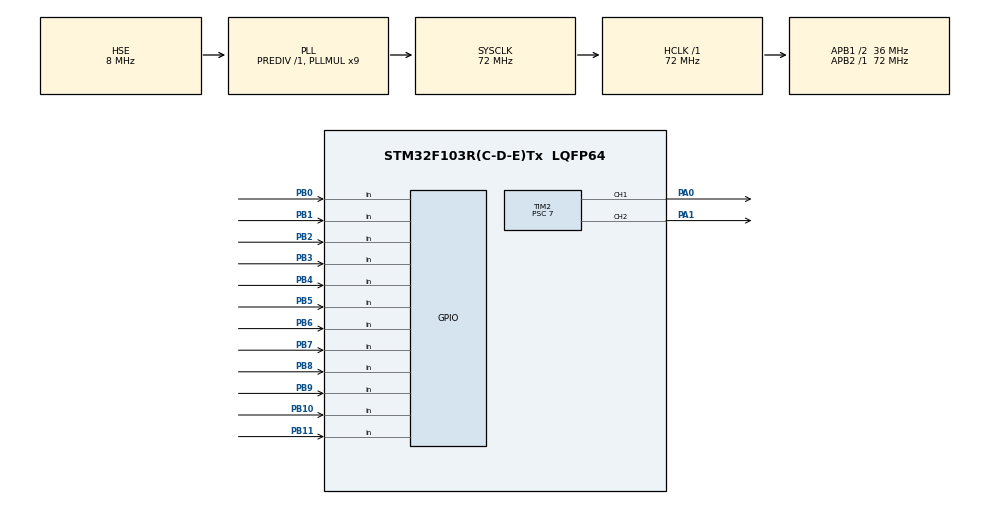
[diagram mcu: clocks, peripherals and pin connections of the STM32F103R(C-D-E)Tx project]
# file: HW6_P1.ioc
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Mcu.Family=STM32F1
Mcu.Name=STM32F103R(C-D-E)Tx
Mcu.Package=LQFP64
NVIC.PriorityGroup=NVIC_PRIORITYGROUP_4
PA0-WKUP.Signal=S_TIM2_CH1_ETR
PA1.Signal=S_TIM2_CH2
PA13.Mode=Serial_Wire
PA13.Signal=SYS_JTMS-SWDIO
PA14.Mode=Serial_Wire
PA14.Signal=SYS_JTCK-SWCLK
PB0.GPIO_PuPd=GPIO_PULLDOWN
PB0.Signal=GPIO_Input
PB1.GPIO_PuPd=GPIO_PULLDOWN
PB1.Signal=GPIO_Input
PB10.GPIO_PuPd=GPIO_PULLDOWN
PB10.Signal=GPIO_Input
PB11.GPIO_PuPd=GPIO_PULLDOWN
PB11.Signal=GPIO_Input
PB2.GPIO_PuPd=GPIO_PULLDOWN
PB2.Signal=GPIO_Input
PB3.GPIO_PuPd=GPIO_PULLDOWN
PB3.Signal=GPIO_Input
PB4.GPIO_PuPd=GPIO_PULLDOWN
PB4.Signal=GPIO_Input
PB5.GPIO_PuPd=GPIO_PULLDOWN
PB5.Signal=GPIO_Input
PB6.GPIO_PuPd=GPIO_PULLDOWN
PB6.Signal=GPIO_Input
PB7.GPIO_PuPd=GPIO_PULLDOWN
PB7.Signal=GPIO_Input
PB8.GPIO_PuPd=GPIO_PULLDOWN
PB8.Signal=GPIO_Input
PB9.GPIO_PuPd=GPIO_PULLDOWN
PB9.Signal=GPIO_Input
PD0-OSC_IN.Mode=HSE-External-Oscillator
PD0-OSC_IN.Signal=RCC_OSC_IN
PD1-OSC_OUT.Mode=HSE-External-Oscillator
PD1-OSC_OUT.Signal=RCC_OSC_OUT
ProjectManager.HeapSize=0x200
ProjectManager.StackSize=0x400
ProjectManager.TargetToolchain=MDK-ARM V5.32
RCC.AHBFreq_Value=72000000
RCC.APB1CLKDivider=RCC_HCLK_DIV2
RCC.APB1Freq_Value=36000000
RCC.APB1TimFreq_Value=72000000
RCC.APB2Freq_Value=72000000
RCC.APB2TimFreq_Value=72000000
RCC.HCLKFreq_Value=72000000
RCC.PLLMUL=RCC_PLL_MUL9
RCC.PLLSourceVirtual=RCC_PLLSOURCE_HSE
RCC.SYSCLKFreq_VALUE=72000000
RCC.SYSCLKSource=RCC_SYSCLKSOURCE_PLLCLK
RCC.USBFreq_Value=72000000
SH.S_TIM2_CH1_ETR.0=TIM2_CH1,PWM Generation1 CH1
SH.S_TIM2_CH2.0=TIM2_CH2,PWM Generation2 CH2
TIM2.Channel-PWM\ Generation1\ CH1=TIM_CHANNEL_1
TIM2.Channel-PWM\ Generation2\ CH2=TIM_CHANNEL_2
TIM2.OCMode_PWM-PWM\ Generation2\ CH2=TIM_OCMODE_PWM1
TIM2.OCPolarity_2=TIM_OCPOLARITY_LOW
TIM2.Period=4499
TIM2.Prescaler=7
VP_TIM2_VS_ClockSourceINT.Mode=Internal
board=custom

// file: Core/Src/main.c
/* USER CODE BEGIN Header */
/**
  ******************************************************************************
  * @file           : main.c
  * @brief          : Main program body
  ******************************************************************************
  * @attention
  *
  * Copyright (c) 2026 STMicroelectronics.
  * All rights reserved.
  *
  * This software is licensed under terms that can be found in the LICENSE file
  * in the root directory of this software component.
  * If no LICENSE file comes with this software, it is provided AS-IS.
  *
  ******************************************************************************
  */
/* USER CODE END Header */
#include "main.h"

TIM_HandleTypeDef htim2;

void SystemClock_Config(void);
static void MX_GPIO_Init(void);
static void MX_TIM2_Init(void);

int main(void)
{

  /* MCU Configuration--------------------------------------------------------*/

  /* Reset of all peripherals, Initializes the Flash interface and the Systick. */
  HAL_Init();

  /* Configure the system clock */
  SystemClock_Config();

  /* Initialize all configured peripherals */
  MX_GPIO_Init();
  MX_TIM2_Init();
  /* USER CODE BEGIN 2 */
	HAL_TIM_PWM_Start(&htim2, TIM_CHANNEL_1);
  HAL_TIM_PWM_Start(&htim2, TIM_CHANNEL_2);
  /* USER CODE END 2 */

  /* Infinite loop */
  while (1)
  {

    /* USER CODE BEGIN 3 */
		// 1. Read Port B and mask the first 12 bits
    uint16_t portB_read = GPIOB->IDR & 0x0FFF;

    // 2. Map the 12-bit input to the ARR range
    uint32_t mapped_duty = ((uint32_t)portB_read * 4500) / 4095;

    // 3. Set the Duty Cycle for Channel 1 (Standard Polarity)
    __HAL_TIM_SET_COMPARE(&htim2, TIM_CHANNEL_1, mapped_duty);

    // 4. Set the Duty Cycle for Channel 2 (Inverted Polarity)
    __HAL_TIM_SET_COMPARE(&htim2, TIM_CHANNEL_2, mapped_duty);

    // Small delay for Proteus simulation stability
    HAL_Delay(10);
  }
  /* USER CODE END 3 */
}

void SystemClock_Config(void)
{
  RCC_OscInitTypeDef RCC_OscInitStruct = {0};
  RCC_ClkInitTypeDef RCC_ClkInitStruct = {0};

  /** Initializes the RCC Oscillators according to the specified parameters
  * in the RCC_OscInitTypeDef structure.
  */
  RCC_OscInitStruct.OscillatorType = RCC_OSCILLATORTYPE_HSE;
  RCC_OscInitStruct.HSEState = RCC_HSE_ON;
  RCC_OscInitStruct.HSEPredivValue = RCC_HSE_PREDIV_DIV1;
  RCC_OscInitStruct.HSIState = RCC_HSI_ON;
  RCC_OscInitStruct.PLL.PLLState = RCC_PLL_ON;
  RCC_OscInitStruct.PLL.PLLSource = RCC_PLLSOURCE_HSE;
  RCC_OscInitStruct.PLL.PLLMUL = RCC_PLL_MUL9;
  if (HAL_RCC_OscConfig(&RCC_OscInitStruct) != HAL_OK)
  {
    Error_Handler();
  }

  /** Initializes the CPU, AHB and APB buses clocks
  */
  RCC_ClkInitStruct.ClockType = RCC_CLOCKTYPE_HCLK|RCC_CLOCKTYPE_SYSCLK
                              |RCC_CLOCKTYPE_PCLK1|RCC_CLOCKTYPE_PCLK2;
  RCC_ClkInitStruct.SYSCLKSource = RCC_SYSCLKSOURCE_PLLCLK;
  RCC_ClkInitStruct.AHBCLKDivider = RCC_SYSCLK_DIV1;
  RCC_ClkInitStruct.APB1CLKDivider = RCC_HCLK_DIV2;
  RCC_ClkInitStruct.APB2CLKDivider = RCC_HCLK_DIV1;

  if (HAL_RCC_ClockConfig(&RCC_ClkInitStruct, FLASH_LATENCY_2) != HAL_OK)
  {
    Error_Handler();
  }
}

static void MX_TIM2_Init(void)
{

  TIM_ClockConfigTypeDef sClockSourceConfig = {0};
  TIM_MasterConfigTypeDef sMasterConfig = {0};
  TIM_OC_InitTypeDef sConfigOC = {0};

  htim2.Instance = TIM2;
  htim2.Init.Prescaler = 7;
  htim2.Init.CounterMode = TIM_COUNTERMODE_UP;
  htim2.Init.Period = 4499;
  htim2.Init.ClockDivision = TIM_CLOCKDIVISION_DIV1;
  htim2.Init.AutoReloadPreload = TIM_AUTORELOAD_PRELOAD_DISABLE;
  if (HAL_TIM_Base_Init(&htim2) != HAL_OK)
  {
    Error_Handler();
  }
  sClockSourceConfig.ClockSource = TIM_CLOCKSOURCE_INTERNAL;
  if (HAL_TIM_ConfigClockSource(&htim2, &sClockSourceConfig) != HAL_OK)
  {
    Error_Handler();
  }
  if (HAL_TIM_PWM_Init(&htim2) != HAL_OK)
  {
    Error_Handler();
  }
  sMasterConfig.MasterOutputTrigger = TIM_TRGO_RESET;
  sMasterConfig.MasterSlaveMode = TIM_MASTERSLAVEMODE_DISABLE;
  if (HAL_TIMEx_MasterConfigSynchronization(&htim2, &sMasterConfig) != HAL_OK)
  {
    Error_Handler();
  }
  sConfigOC.OCMode = TIM_OCMODE_PWM1;
  sConfigOC.Pulse = 0;
  sConfigOC.OCPolarity = TIM_OCPOLARITY_HIGH;
  sConfigOC.OCFastMode = TIM_OCFAST_DISABLE;
  if (HAL_TIM_PWM_ConfigChannel(&htim2, &sConfigOC, TIM_CHANNEL_1) != HAL_OK)
  {
    Error_Handler();
  }
  sConfigOC.OCPolarity = TIM_OCPOLARITY_LOW;
  if (HAL_TIM_PWM_ConfigChannel(&htim2, &sConfigOC, TIM_CHANNEL_2) != HAL_OK)
  {
    Error_Handler();
  }
  HAL_TIM_MspPostInit(&htim2);

}

static void MX_GPIO_Init(void)
{
  GPIO_InitTypeDef GPIO_InitStruct = {0};

  /* GPIO Ports Clock Enable */
  __HAL_RCC_GPIOD_CLK_ENABLE();
  __HAL_RCC_GPIOA_CLK_ENABLE();
  __HAL_RCC_GPIOB_CLK_ENABLE();

  /*Configure GPIO pins : PB0 PB1 PB2 PB10
                           PB11 PB3 PB4 PB5
                           PB6 PB7 PB8 PB9 */
  GPIO_InitStruct.Pin = GPIO_PIN_0|GPIO_PIN_1|GPIO_PIN_2|GPIO_PIN_10
                          |GPIO_PIN_11|GPIO_PIN_3|GPIO_PIN_4|GPIO_PIN_5
                          |GPIO_PIN_6|GPIO_PIN_7|GPIO_PIN_8|GPIO_PIN_9;
  GPIO_InitStruct.Mode = GPIO_MODE_INPUT;
  GPIO_InitStruct.Pull = GPIO_PULLDOWN;
  HAL_GPIO_Init(GPIOB, &GPIO_InitStruct);

}

void Error_Handler(void)
{
  __disable_irq();
  while (1)
  {
  }
}
